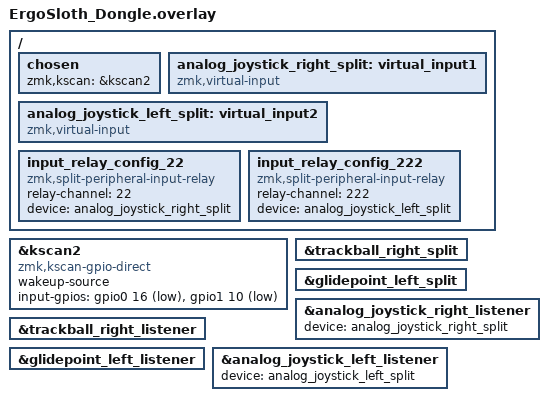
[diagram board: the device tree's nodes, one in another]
#include "ErgoSloth.dtsi"

/ {
    chosen {
        zmk,kscan = &kscan2;
    };

    /* define virtual input, will be resurrected for emitting input event */
	/* NOTE: set `device = <&analog_joystick_right_split>` in `zmk,input-listener` */
	analog_joystick_right_split: virtual_input1 {
		compatible = "zmk,virtual-input";
	};

	analog_joystick_left_split: virtual_input2 {
		compatible = "zmk,virtual-input";
	};

	/* for central side, define (relay-channel)-to-(virtual-input) mapping */
	input_relay_config_22 {
		compatible = "zmk,split-peripheral-input-relay";
		/* channel id, used to filter incoming input event from split peripheral */
		/* NOTE: should matching relay-channel on peripheral overlay */
		relay-channel = <22>;
		/* virtual input device on central, which used to emit input event as an agent device */
		device = <&analog_joystick_right_split>;
	};

	input_relay_config_222 {
		compatible = "zmk,split-peripheral-input-relay";
		relay-channel = <222>;
		device = <&analog_joystick_left_split>;
	};

};

&kscan2 {
      compatible = "zmk,kscan-gpio-direct";
        wakeup-source;
        input-gpios
			= <&gpio0 16 (GPIO_ACTIVE_LOW | GPIO_PULL_UP)>
			, <&gpio1 10 (GPIO_ACTIVE_LOW | GPIO_PULL_UP)>
			;
};

&trackball_right_split {
	status = "okay";
};

&glidepoint_left_split {
	status = "okay";
};

// listeners
&analog_joystick_right_listener {
	device = <&analog_joystick_right_split>;
	status = "okay";
};

&trackball_right_listener {
    status = "okay";
};

&glidepoint_left_listener {
    status = "okay";
};

&analog_joystick_left_listener {
	device = <&analog_joystick_left_split>;
	status = "okay";
};
